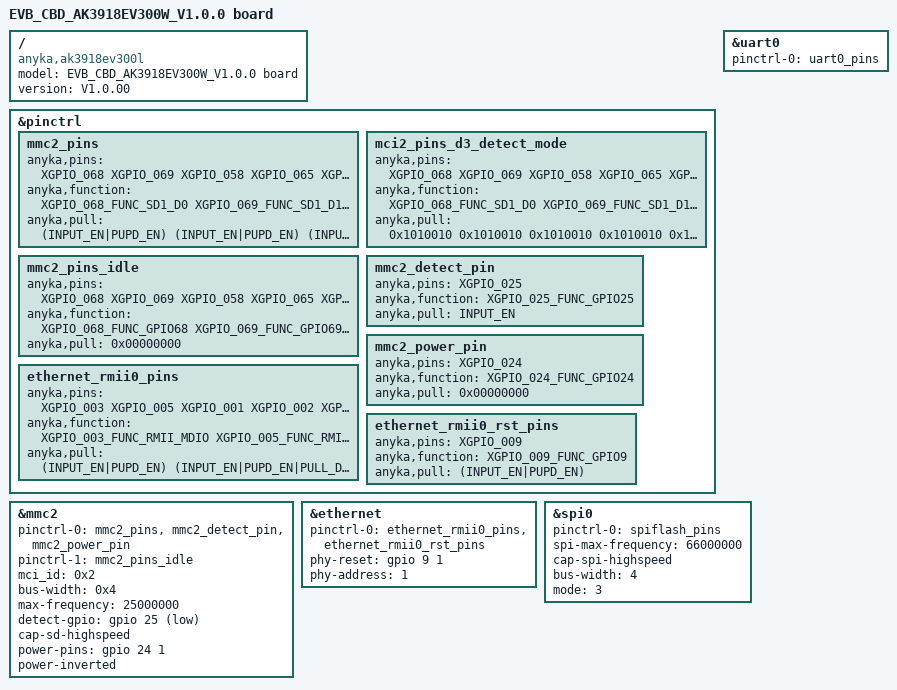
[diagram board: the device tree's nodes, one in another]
/*
 * Anycloud3918ev300l develop board dts
 *
 * Copyright (C) 2020 Anyka(Guangzhou) Microelectronics Technology Co., Ltd.
 *
 * This program is free software; you can redistribute it and/or modify
 * it under the terms of the GNU General Public License as published by
 * the Free Software Foundation; either version 2 of the License, or
 * (at your option) any later version.
 *
 * This program is distributed in the hope that it will be useful,
 * but WITHOUT ANY WARRANTY; without even the implied warranty of
 * MERCHANTABILITY or FITNESS FOR A PARTICULAR PURPOSE.  See the
 * GNU General Public License for more details.
 */

/dts-v1/;
#include "anycloud_ak3918ev300l.dtsi"
#include "anycloud_ak3918ev300l_pinctrl.dtsi"

/ {
    compatible = "anyka,ak3918ev300l";
    model = "EVB_CBD_AK3918EV300W_V1.0.0 board";
    version = "V1.0.00";
};

&pinctrl {
    /*
    * "anyka,function": func index, please refer to dt-bindings/pinctrl/ak_3918ev300l_pinctrl.h
    * "anyka,pull": configuration of the pins
    * bit[7:0]: pull up/down configuration
    *     bit[0]: pull up or pull down selection, 1 means select pull down, 0 means select pull up
    *     bit[4]: pull up or pull down enable, 1 means enable pull up&down function, 0 means disable fuction
    * !!! Notice that not all pin support pull up and pull down. Please refer to the programer's guide.
    * bit[15:8]: driver strength configuration.
    *     bit[9:8] drive strength.
    * bit[23:16]: input enable configuration
    *     bit[16]: 1 means enable input, 0 means disable input.
    * bit[31:24]: pin slew rate configuration
    *     bit[24]: 1 means enable slew rate, 0 means disable slew rate.
    * !!! Notice OTHER bits which not mentioned please set to 0.
    */

    mmc2_pins: mmc2_pins {
        anyka,pins = <XGPIO_068 XGPIO_069 XGPIO_058 XGPIO_065 XGPIO_066 XGPIO_067>;
        anyka,function = <XGPIO_068_FUNC_SD1_D0
                            XGPIO_069_FUNC_SD1_D1
                            XGPIO_058_FUNC_SD1_CMD
                            XGPIO_065_FUNC_SD1_MCLK
                            XGPIO_066_FUNC_SD1_D2
                            XGPIO_067_FUNC_SD1_D3>;

        anyka,pull = <(INPUT_EN|PUPD_EN)
						(INPUT_EN|PUPD_EN)
						(INPUT_EN|PUPD_EN)
						(INPUT_EN|PULL_DOWN)
						(INPUT_EN|PUPD_EN)
						(INPUT_EN|PUPD_EN)
						>;
    };

	/* 
     *  When using DATA3 as plugin and plugoff detect:
     *  1. Set XGPIO_032_FUNC_SDIO0_DATA3 pull up disable and pull down disable
     *  2. Using PULLDOWN RESISTANCE on PCB, for example, 510K.
    */      
    mci2_pins_d3_detect_mode: mci2_pins_d3_detect_mode {
        anyka,pins = <XGPIO_068 XGPIO_069 XGPIO_058 XGPIO_065 XGPIO_066 XGPIO_067>;
        anyka,function = <XGPIO_068_FUNC_SD1_D0
                            XGPIO_069_FUNC_SD1_D1
                            XGPIO_058_FUNC_SD1_CMD
                            XGPIO_065_FUNC_SD1_MCLK
                            XGPIO_066_FUNC_SD1_D2
                            XGPIO_067_FUNC_SD1_D3>;
        anyka,pull = <  0x1010010 
                        0x1010010
                        0x1010010
                        0x1010010  
                        0x1010010
                        0x1010001>;/* disable pull down and pull up */
    };
    
    mmc2_pins_idle: mmc2_pins_idle {
        anyka,pins = <XGPIO_068 XGPIO_069 XGPIO_058 XGPIO_065 XGPIO_066 XGPIO_067>;
        anyka,function = <XGPIO_068_FUNC_GPIO68
                            XGPIO_069_FUNC_GPIO69
                            XGPIO_058_FUNC_GPIO58
                            XGPIO_065_FUNC_GPIO65
                            XGPIO_066_FUNC_GPIO66
                            XGPIO_067_FUNC_GPIO67>;
        anyka,pull = <0x00000000>;
    };

	mmc2_detect_pin: mmc2_detect_pin {
        anyka,pins = <XGPIO_025>;
        anyka,function = <XGPIO_025_FUNC_GPIO25>;
        anyka,pull = <INPUT_EN>;
    };
    
    mmc2_power_pin: mmc2_power_pin {
        anyka,pins = <XGPIO_024>;
        anyka,function = <XGPIO_024_FUNC_GPIO24>;
        anyka,pull = <0x00000000>;
    };

    ethernet_rmii0_pins: ethernet_rmii0_pins {
        anyka,pins = <XGPIO_003
                        XGPIO_005
                        XGPIO_001
                        XGPIO_002
                        XGPIO_011
                        XGPIO_006
                        XGPIO_000
                        XGPIO_007
                        XGPIO_008
                        XGPIO_004>;
        anyka,function = <XGPIO_003_FUNC_RMII_MDIO
                            XGPIO_005_FUNC_RMII_MDC
                            XGPIO_001_FUNC_RMII_RXER
                            XGPIO_002_FUNC_RMII_RXDV
                            XGPIO_011_FUNC_RMII_RXD0
                            XGPIO_006_FUNC_RMII_RXD1
                            XGPIO_000_FUNC_OPCLK1
                            XGPIO_007_FUNC_RMII_TXD0
                            XGPIO_008_FUNC_RMII_TXD1
                            XGPIO_004_FUNC_RMII_TXEN
                            >;
        anyka,pull = <(INPUT_EN|PUPD_EN)
						(INPUT_EN|PUPD_EN|PULL_DOWN)
						(INPUT_EN|PUPD_EN|PULL_DOWN)
						(INPUT_EN|PUPD_EN|PULL_DOWN)
						(INPUT_EN|PUPD_EN|PULL_DOWN)
						(INPUT_EN|PUPD_EN|PULL_DOWN)
						(DRIVE_08MA|INPUT_EN)
						(FAST_CTRL|INPUT_EN|PUPD_EN|PULL_DOWN)
						(FAST_CTRL|INPUT_EN|PUPD_EN|PULL_DOWN)
 						(INPUT_EN|PUPD_EN|PULL_DOWN)
						>; 
	};

    ethernet_rmii0_rst_pins: ethernet_rmii0_rst_pins {
        anyka,pins = <XGPIO_009>;
        anyka,function = <XGPIO_009_FUNC_GPIO9>;
        anyka,pull = <(INPUT_EN|PUPD_EN)>;
    };
};

&mmc2 {
    pinctrl-names = "default","idle";
    pinctrl-0 = <&mmc2_pins &mmc2_detect_pin &mmc2_power_pin>;
    pinctrl-1 = <&mmc2_pins_idle>;

	mci_id = <0x2>;  //for mmc id
    bus-width = <0x4>;
    max-frequency = <25000000>;
    /*
     *  detect mode:
     *  (1) non-removable;
     *  (2) detect-gpio/detect-gpios: card detect using gpio
     *      for example:
     *      detect-gpio = <&gpio 76 1>;  or detect-gpios = <&gpio 76 1>;
     *  (3) cd_clk: card detect using MCLK
     */
    detect-gpio = <&gpio 25 1>; 
    /* if support highspeed, using cap-sd-highspeed */
    cap-sd-highspeed; 
    /*
    * support tf card circuit enable function
    */
    power-pins = <&gpio 24 1>;      //power-pins is which tf_en_pins describes
    power-inverted;
    status = "okay";
};

/* mmc1 card detect using  cd_clk*/
/*
&mmc2 {
    pinctrl-names = "default","idle";
    //pinctrl-0 = <&mmc2_pins &mmc2_detect_pin &mmc2_power_pin>;
    pinctrl-0 = <&mmc2_pins &mmc2_power_pin>;
    pinctrl-1 = <&mmc2_pins_idle>;

	mci_id = <0x2>;  //for mmc id
    bus-width = <0x4>;
    max-frequency = <25000000>;
    cd_clk;
    // if support highspeed, using cap-sd-highspeed
    cap-sd-highspeed; 
    //support tf card circuit enable function 
    power-pins = <&gpio 24 1>;      //power-pins is which tf_en_pins describes
    power-inverted;
    status = "okay";
};
*/

/* mmc1 card detect using cd_d3 */
/*
&mmc2 {
    pinctrl-names = "default","idle";
    pinctrl-0 = <&mci2_pins_d3_detect_mode &mmc2_power_pin>;
    pinctrl-1 = <&mmc2_pins_idle>;

	mci_id = <0x2>;  //for mmc id
    bus-width = <0x4>;
    max-frequency = <25000000>;

    cd_d3;
    // if support highspeed, using cap-sd-highspeed 
    cap-sd-highspeed; 
    //support tf card circuit enable function    
    power-pins = <&gpio 24 1>;      //power-pins is which tf_en_pins describes
    power-inverted;
    status = "okay";
};
*/
    
&ethernet {
    pinctrl-names = "default";
	pinctrl-0 = <&ethernet_rmii0_pins &ethernet_rmii0_rst_pins>;
    phy-reset = <&gpio 9 1>; 
    //phy-reset = <&gpio 24 1>;
	phy-address = <1>;

	status = "okay";
	    
};

&uart0 {
    pinctrl-names = "default";
    pinctrl-0 = <&uart0_pins>;
    status = "okay";
};

&spi0 {
    pinctrl-names = "default";
    pinctrl-0 = <&spiflash_pins>;
     /*pinctrl-names = "default";*/
     /*pinctrl-0 = <&spiflash_pins>;*/
    spi-max-frequency = <66000000>;
    /*
     * cap-spi-highspeed;
     * if defined, means high speed controller(Maximum 80M/s);
     * if not, means normal speed controller(below 60M/s)
     */
    cap-spi-highspeed;
    /* spi flash data bus width:
        ** 1 means 1 wire mode.
        ** 2 means 2 wire mode
        ** 4 means 4 wire mode.
        ** default: 4 wire mode.
        **/
    bus-width = <4>;
    mode = <3>; /* spi mode selected  */  
    status = "okay";
};

